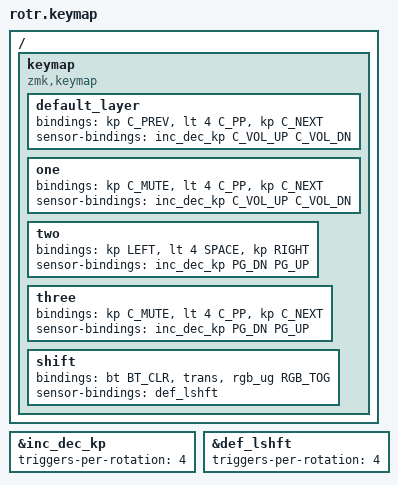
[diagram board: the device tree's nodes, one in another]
#include <behaviors.dtsi>
#include <dt-bindings/zmk/keys.h>
#include <dt-bindings/zmk/rgb.h>
#include <dt-bindings/zmk/bt.h>

&inc_dec_kp {
	triggers-per-rotation = <4>;
};
&def_lshft {
	triggers-per-rotation = <4>;
};

/ {
	keymap {
		compatible = "zmk,keymap";

		default_layer {
			//RED LED
			//PREV | PLAY/PAUSE | NEXT
			bindings = <&kp C_PREV &lt 4 C_PP &kp C_NEXT>;
			//<-- VOL UP | VOL DOWN -->
			sensor-bindings = <&inc_dec_kp C_VOL_UP C_VOL_DN>;
		};
		one {
			//GREEN LED
			//MUTE | PLAY/PAUSE | NEXT
			bindings = <&kp C_MUTE &lt 4 C_PP &kp C_NEXT>;
			//<-- VOL UP | VOL DOWN -->
			sensor-bindings = <&inc_dec_kp C_VOL_UP C_VOL_DN>;
		};
		two {
			//BLUE LED
			//LEFT | SPACE | RIGHT
			bindings = <&kp LEFT &lt 4 SPACE &kp RIGHT>;
			//<-- PG DOWN | PG UP -->
			sensor-bindings = <&inc_dec_kp PG_DN PG_UP>;
		};
		three {
			//YELLOW LED
			//MUTE | PLAY/PAUSE | NEXT
			bindings = <&kp C_MUTE &lt 4 C_PP &kp C_NEXT>;
			//<-- PG DOWN | PG UP -->
			sensor-bindings = <&inc_dec_kp PG_DN PG_UP>;
		};
		shift {
			//BT CLR | ______ | RGB TOG
			bindings = <&bt BT_CLR &trans &rgb_ug RGB_TOG>;
			//LAYER SHIFT
			sensor-bindings = <&def_lshft>;
		};
	};
};
